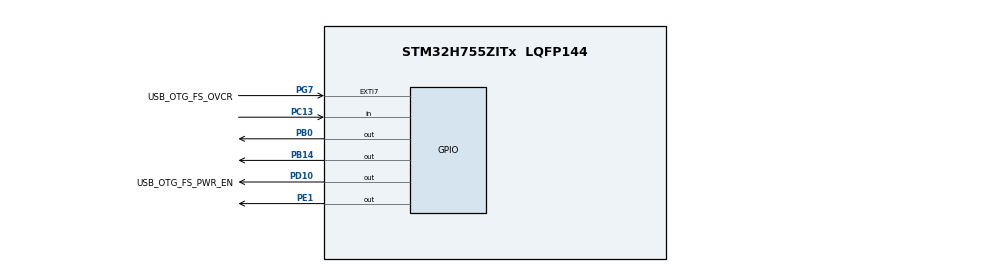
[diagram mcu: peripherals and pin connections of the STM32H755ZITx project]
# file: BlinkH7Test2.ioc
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CortexM4.IPs=FATFS_M4\:I,FREERTOS_M4\:I,IWDG2\:I,RCC,WWDG2\:I,DMA,BDMA,MDMA,NVIC2\:I,ETH,USART3,DEBUG,PDM2PCM_M4\:I,PWR,RESMGR_UTILITY,SYS_M4\:I,USB_DEVICE_M4\:I,USB_HOST_M4\:I,CORTEX_M4\:I,GPIO,OPENAMP_M4\:I,VREFBUF,NUCLEO-H755ZI-Q
CortexM7.IPs=FATFS_M7\:I,FREERTOS_M7\:I,IWDG1\:I,RCC\:I,WWDG1\:I,DMA\:I,BDMA\:I,MDMA\:I,NVIC1\:I,ETH\:I,USART3\:I,USB_OTG_FS\:I,SYS\:I,CORTEX_M7\:I,DEBUG\:I,PDM2PCM_M7\:I,PWR\:I,RESMGR_UTILITY\:I,USB_DEVICE_M7\:I,USB_HOST_M7\:I,GPIO\:I,OPENAMP_M7\:I,VREFBUF\:I,NUCLEO-H755ZI-Q\:I
Mcu.Family=STM32H7
Mcu.Name=STM32H755ZITx
Mcu.Package=LQFP144
NUCLEO-H755ZI-Q.BUTTON=1
NUCLEO-H755ZI-Q.LD1=true
NUCLEO-H755ZI-Q.LD2=true
NUCLEO-H755ZI-Q.LD3=true
NUCLEO-H755ZI-Q.VCP=true
NVIC1.EXTI15_10_IRQn=true\:0\:0\:false\:false\:true\:false\:true\:true
NVIC1.PriorityGroup=NVIC_PRIORITYGROUP_4
NVIC2.PriorityGroup=NVIC_PRIORITYGROUP_4
PA1.Signal=ETH_REF_CLK
PA11.Signal=USB_OTG_FS_DM
PA12.Signal=USB_OTG_FS_DP
PA2.Signal=ETH_MDIO
PA7.Signal=ETH_CRS_DV
PA8.Signal=USB_OTG_FS_SOF
PA9.Signal=USB_OTG_FS_VBUS
PB0.Signal=GPIO_Output
PB13.Signal=ETH_TXD1
PB14.Signal=GPIO_Output
PC1.Signal=ETH_MDC
PC13.Signal=GPIO_Input
PC14-OSC32_IN\ (OSC32_IN).Signal=RCC_OSC32_IN
PC15-OSC32_OUT\ (OSC32_OUT).Signal=RCC_OSC32_OUT
PC4.Signal=ETH_RXD0
PC5.Signal=ETH_RXD1
PD10.GPIO_Label=USB_OTG_FS_PWR_EN
PD10.Signal=GPIO_Output
PD8.Signal=USART3_TX
PD9.Signal=USART3_RX
PE1.Signal=GPIO_Output
PG11.Signal=ETH_TX_EN
PG13.Signal=ETH_TXD0
PG7.GPIO_Label=USB_OTG_FS_OVCR
PG7.Signal=GPXTI7
PH0-OSC_IN\ (PH0).Signal=RCC_OSC_IN
PH1-OSC_OUT\ (PH1).Signal=RCC_OSC_OUT
ProjectManager.HeapSize=M4-0x200,M7-0x200
ProjectManager.StackSize=M4-0x400,M7-0x400
ProjectManager.TargetToolchain=CMake
RCC.ADCFreq_Value=129000000
RCC.APB1Freq_Value=64000000
RCC.APB2Freq_Value=64000000
RCC.APB3Freq_Value=64000000
RCC.APB4Freq_Value=64000000
RCC.CortexFreq_Value=64000000
RCC.DIVM1=5
RCC.DIVN1=48
RCC.DIVQ1=5
RCC.HCLKFreq_Value=64000000
RCC.PLL2FRACN=0
RCC.PLL3FRACN=0
RCC.PLLFRACN=0
RCC.SYSCLKFreq_VALUE=64000000
RCC.SupplySource=PWR_DIRECT_SMPS_SUPPLY
RCC.USBFreq_Value=122880000
VP_NUCLEO-H755ZI-Q_VS_BSP_COMMON.Mode=COMMON
VP_SYS_M4_VS_Systick.Mode=SysTick
board=NUCLEO-H755ZI-Q

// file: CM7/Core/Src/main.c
/* USER CODE BEGIN Header */
/**
  ******************************************************************************
  * @file           : main.c
  * @brief          : Main program body
  ******************************************************************************
  * @attention
  *
  * Copyright (c) 2025 STMicroelectronics.
  * All rights reserved.
  *
  * This software is licensed under terms that can be found in the LICENSE file
  * in the root directory of this software component.
  * If no LICENSE file comes with this software, it is provided AS-IS.
  *
  ******************************************************************************
  */
/* USER CODE END Header */
#include "main.h"

/* USER CODE BEGIN PD */

#ifndef HSEM_ID_0
#define HSEM_ID_0 (0U) /* HW semaphore 0*/
#endif

/* USER CODE END PD */

COM_InitTypeDef BspCOMInit;

/* USER CODE BEGIN PV */
uint8_t count = 0;
/* USER CODE END PV */

void SystemClock_Config(void);

int main(void)
{

/* USER CODE BEGIN Boot_Mode_Sequence_0 */
  int32_t timeout;
/* USER CODE END Boot_Mode_Sequence_0 */

/* USER CODE BEGIN Boot_Mode_Sequence_1 */
  /* Wait until CPU2 boots and enters in stop mode or timeout*/
  /*timeout = 0xFFFF;
  while((__HAL_RCC_GET_FLAG(RCC_FLAG_D2CKRDY) != RESET) && (timeout-- > 0));
  if ( timeout < 0 )
  {
  Error_Handler();
  }*/
  while (__HAL_RCC_GET_FLAG(RCC_FLAG_D2CKRDY) != RESET)
  {
      //asm("nop");
  }
/* USER CODE END Boot_Mode_Sequence_1 */
  /* MCU Configuration--------------------------------------------------------*/

  /* Reset of all peripherals, Initializes the Flash interface and the Systick. */
  HAL_Init();

  /* Configure the system clock */
  SystemClock_Config();
/* USER CODE BEGIN Boot_Mode_Sequence_2 */
/* When system initialization is finished, Cortex-M7 will release Cortex-M4 by means of
HSEM notification */
/*HW semaphore Clock enable*/
__HAL_RCC_HSEM_CLK_ENABLE();
/*Take HSEM */
HAL_HSEM_FastTake(HSEM_ID_0);
/*Release HSEM in order to notify the CPU2(CM4)*/
HAL_HSEM_Release(HSEM_ID_0,0);
/* wait until CPU2 wakes up from stop mode */
timeout = 0xFFFF;
while((__HAL_RCC_GET_FLAG(RCC_FLAG_D2CKRDY) == RESET) && (timeout-- > 0));
if ( timeout < 0 )
{
Error_Handler();
}
/* USER CODE END Boot_Mode_Sequence_2 */

  /* Initialize all configured peripherals */

  /* Initialize leds */
  BSP_LED_Init(LED_GREEN);
  BSP_LED_Init(LED_YELLOW);
  BSP_LED_Init(LED_RED);

  /* Initialize USER push-button, will be used to trigger an interrupt each time it's pressed.*/
  BSP_PB_Init(BUTTON_USER, BUTTON_MODE_EXTI);

  /* Initialize COM1 port (115200, 8 bits (7-bit data + 1 stop bit), no parity */
  BspCOMInit.BaudRate   = 115200;
  BspCOMInit.WordLength = COM_WORDLENGTH_8B;
  BspCOMInit.StopBits   = COM_STOPBITS_1;
  BspCOMInit.Parity     = COM_PARITY_NONE;
  BspCOMInit.HwFlowCtl  = COM_HWCONTROL_NONE;
  if (BSP_COM_Init(COM1, &BspCOMInit) != BSP_ERROR_NONE)
  {
    Error_Handler();
  }

  /* Infinite loop */
  /* USER CODE BEGIN WHILE */
  while (1)
  {
    HAL_GPIO_TogglePin(GPIOB, GPIO_PIN_0); /* Toggle LED_GREEN */
    HAL_Delay(500); /* Delay 500 ms */

    count++;

    /* USER CODE END WHILE */

  }
}

void SystemClock_Config(void)
{
  RCC_OscInitTypeDef RCC_OscInitStruct = {0};
  RCC_ClkInitTypeDef RCC_ClkInitStruct = {0};

  /** Supply configuration update enable
  */
  HAL_PWREx_ConfigSupply(PWR_DIRECT_SMPS_SUPPLY);

  /** Configure the main internal regulator output voltage
  */
  __HAL_PWR_VOLTAGESCALING_CONFIG(PWR_REGULATOR_VOLTAGE_SCALE3);

  while(!__HAL_PWR_GET_FLAG(PWR_FLAG_VOSRDY)) {}

  /** Initializes the RCC Oscillators according to the specified parameters
  * in the RCC_OscInitTypeDef structure.
  */
  RCC_OscInitStruct.OscillatorType = RCC_OSCILLATORTYPE_HSI;
  RCC_OscInitStruct.HSIState = RCC_HSI_DIV1;
  RCC_OscInitStruct.HSICalibrationValue = RCC_HSICALIBRATION_DEFAULT;
  RCC_OscInitStruct.PLL.PLLState = RCC_PLL_NONE;
  if (HAL_RCC_OscConfig(&RCC_OscInitStruct) != HAL_OK)
  {
    Error_Handler();
  }

  /** Initializes the CPU, AHB and APB buses clocks
  */
  RCC_ClkInitStruct.ClockType = RCC_CLOCKTYPE_HCLK|RCC_CLOCKTYPE_SYSCLK
                              |RCC_CLOCKTYPE_PCLK1|RCC_CLOCKTYPE_PCLK2
                              |RCC_CLOCKTYPE_D3PCLK1|RCC_CLOCKTYPE_D1PCLK1;
  RCC_ClkInitStruct.SYSCLKSource = RCC_SYSCLKSOURCE_HSI;
  RCC_ClkInitStruct.SYSCLKDivider = RCC_SYSCLK_DIV1;
  RCC_ClkInitStruct.AHBCLKDivider = RCC_HCLK_DIV1;
  RCC_ClkInitStruct.APB3CLKDivider = RCC_APB3_DIV1;
  RCC_ClkInitStruct.APB1CLKDivider = RCC_APB1_DIV1;
  RCC_ClkInitStruct.APB2CLKDivider = RCC_APB2_DIV1;
  RCC_ClkInitStruct.APB4CLKDivider = RCC_APB4_DIV1;

  if (HAL_RCC_ClockConfig(&RCC_ClkInitStruct, FLASH_LATENCY_1) != HAL_OK)
  {
    Error_Handler();
  }
}

void Error_Handler(void)
{
  __disable_irq();
  while (1)
  {
  }
}
